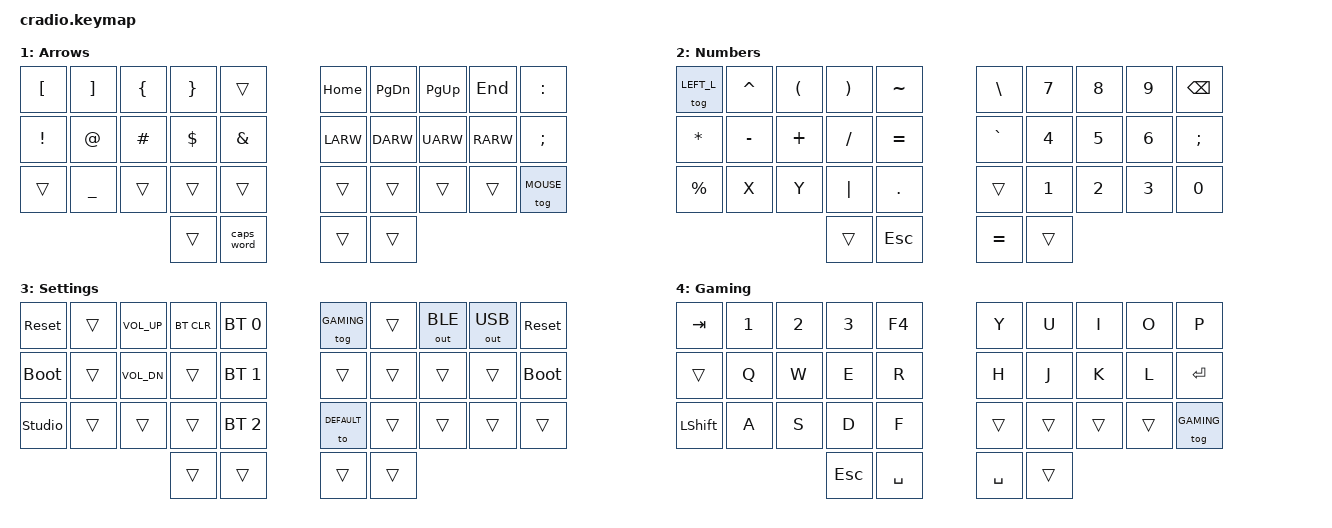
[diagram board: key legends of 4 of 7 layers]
// Copyright (c) 2022 The ZMK Contributors
// SPDX-License-Identifier: MIT

#include <behaviors.dtsi>
#include <dt-bindings/zmk/keys.h>
#include <dt-bindings/zmk/bt.h>
#include <dt-bindings/zmk/outputs.h>

// Homerow mods macro
#define HRML(k1,k2,k3,k4) &ht LSHFT k1 &ht LALT k2  &ht LGUI k3  &ht LCTRL k4
#define HRMR(k1,k2,k3,k4) &ht RCTRL k1  &ht RGUI k2  &ht RALT k3  &ht RSHFT k4
#define HRMLW(k1,k2,k3,k4) &ht LSHFT k1 &ht LALT k2  &ht LCTRL k3  &ht LGUI k4
#define HRMRW(k1,k2,k3,k4) &ht RGUI k1  &ht RCTRL k2  &ht RALT k3  &ht RSHFT k4 
// Layers
#define DEFAULT 0
#define RIGHT_L 1 
#define LEFT_L 2 
#define SETTINGS 3
#define GAMING 4
#define MOUSE 5
#define MEDIA 6 

// Combo Funct
#define COMBO(NAME, BINDINGS, LAYERS, KEYPOS) \
    combo_##NAME { \
        timeout-ms = <50>; \
        bindings = <BINDINGS>; \
        key-positions = <KEYPOS>; \
        layers = <LAYERS>;  \
    };

// Tap Function
/*#define TAP(NAME, keyType, BINDINGS1, keyType2, BINDINGS2, keyType3, BINDINGS3) \
    t_##NAME: tap_##NAME { \
        compatible = "zmk,behavior-tap-dance"; \
        label = "tap##Name"; \
        #binding-cells = <0>; \
        tapping-term-ms = <250>; \
        bindings = <keyType BINDINGS1>, <keyType2 BINDINGS2>, <keyType3 BINDINGS3>; \
    };
*/

/ {
    behaviors {

        ht: hold_tap {
            label = "hold_tap";
            compatible = "zmk,behavior-hold-tap";
            #binding-cells = <2>;
            flavor = "tap-preferred";
            tapping-term-ms = <220>;
            quick-tap-ms = <1>;
            require-prior-idle-ms = <100>;
            bindings = <&kp>, <&kp>;
        };

        numPad: numPad_tap {
            compatible = "zmk,behavior-tap-dance";
            label = "numPad";
            #binding-cells = <0>;
            tapping-term-ms = <250>;
            bindings = <&kp SPACE>, <&tog MOUSE>;
        };

        dt: delete_Tap {
            compatible = "zmk,behavior-tap-dance";
            label = "DELETE_TAP";
            #binding-cells = <0>;
            tapping-term-ms = <200>;
            bindings = <&ht LG(BSPC) BSPC>, <&mo 3>;
        };

        ct: copyTap {
            compatible = "zmk,behavior-tap-dance";
            label = "COPY_TAP";
            #binding-cells = <0>;
            tapping-term-ms = <100>;
            bindings = <&ht LG(V) C>, <&kp LG(X)>;
        };

        Enterspace: EnterTap {
            compatible = "zmk,behavior-tap-dance";
            label = "TAP_DANCE_0";
            #binding-cells = <0>;  
            tapping-term-ms = <200>;
            bindings = <&kp SPACE>, <&kp ENTER>;
        };

        ESCspace: EscTap {
            compatible = "zmk,behavior-tap-dance";
            label = "ESC_TAP";
            #binding-cells = <0>;  
            tapping-term-ms = <250>;
            bindings = <&kp SPACE>, <&kp ESC>;
        };

        BTchange: BT_tap {
            compatible = "zmk,behavior-tap-dance";
            label = "BT_TAP";
            #binding-cells = <0>;
            tapping-term-ms = <200>;
            bindings = <&bt BT_SEL 0>, <&bt BT_CLR>;
        };

        ESCP: ESCP_tap {
            compatible = "zmk,behavior-tap-dance";
            label = "ESCP_tap";
            #binding-cells = <0>;
            tapping-term-ms = <200>;
            bindings = <&kp Y>, <&kp ESC>;
        };
	};
};

/{
   macros {
        theMacro: theMacro {
            label = "THEMACRO";
            compatible = "zmk,behavior-macro";
            #binding-cells = <0>;
            bindings
                = <&kp T &kp H &kp E>;
        };

        gitPush: gitPushMacro {
            label = "GITPUSHMACRO";
            compatible = "zmk,behavior-macro";
            #binding-cells = <0>;
            bindings
                = <&kp G &kp I &kp T &kp SPACE &kp P &kp U &kp S &kp H &kp ENTER>;
        };
        
        gitPull: gitPullMacro {
            label = "GITPULLMACRO";
            compatible = "zmk,behavior-macro";
            #binding-cells = <0>;
            bindings
                = <&kp G &kp I &kp T &kp SPACE &kp P &kp U &kp L &kp L &kp ENTER>;
        };

        gitAdd: gitAddMacro {
            label = "GITADDMACRO";
            compatible = "zmk,behavior-macro";
            #binding-cells = <0>;
            bindings
                = <&kp G &kp I &kp T &kp SPACE &kp A &kp D &kp D &kp SPACE &kp DOT &kp ENTER>;
        };

        gitCommit: gitCommitMacro {
            label = "GITCOMMITMACRO";
            compatible = "zmk,behavior-macro";
            #binding-cells = <0>;
            bindings
                = <&kp G &kp I &kp T &kp SPACE &kp C &kp O &kp M &kp M &kp I &kp T &kp SPACE &kp MINUS &kp M &kp SPACE &kp DQT>;
        };

        clear: clearMacro {
            label = "CLEARMACRO";
            compatible = "zmk,behavior-macro";
            #binding-cells = <0>;
            bindings
                = <&kp C &kp L &kp E &kp A &kp R &kp ENTER>;
        };
    };
};

/{
    conditional_layers {
        compatible = "zmk,conditional-layers";
        tri_layer {
            if-layers = <1 2>;
            then-layer = <SETTINGS>;
        };
    };
};

/{
    combos{
        compatible = "zmk,combos";
        COMBO(easyThe, &theMacro, 1, 3 4)
        COMBO(pushCombo, &gitPush, 1, 14 16)
        COMBO(commitCombo, &gitCommit, 1, 14 15)
        COMBO(pullCombo, &gitPull, 1, 2 14)
        COMBO(addCombo, &gitAdd, 1, 3 14)
        COMBO(clearCombo, &kp LC(L), 1, 31 32)
        COMBO(delete, &kp DEL, 1, 8 9)
    };
};

/{    
    //╭──────────┬──────────┬──────────┬──────────┬──────────╮   ╭──────────┬──────────┬──────────┬──────────┬──────────╮
    //│    0     │    1     │    2     │     3    │   4      │   │     5    │   6      │     7    │     8    │    9     │
    //├──────────┼──────────┼──────────┼──────────┼──────────┤   ├──────────┼──────────┼──────────┼──────────┼──────────┤
    //│    10    │    11    │    12    │   13     │   14     │   │   15     │    16    │    17    │    18    │    19    │
    //├──────────┼──────────┼──────────┼──────────┼──────────┤   ├──────────┼──────────┼──────────┼──────────┼──────────┤
    //│     20   │    21    │   22     │   23     │     24   │   │    25    │    26    │   27     │    28    │   29     │
    //╰──────────┴──────────┴──────────┼──────────┼──────────┤   ├──────────┼──────────┼──────────┴──────────┴──────────╯
    //                                 |    30    |     31   |   |    32    |    33    |
    //                                 ╰──────────┴──────────╯   ╰──────────┴──────────╯

    keymap {
        compatible = "zmk,keymap";
        default_layer {
            display-name = "Main";
            bindings = <    
        //╭──────────┬──────────┬──────────┬──────────┬──────────╮   ╭──────────┬──────────┬──────────┬──────────┬──────────╮
        //│  Q       │  W       │  E       │  R       │  T       │   │  Y       │  U       │  I       │  O       │  P       │
            &kp Q      &kp W      &kp E      &kp R      &kp T          &ESCP      &kp U      &kp I      &kp O      &kp P
        //├──────────┼──────────┼──────────┼──────────┼──────────┤   ├──────────┼──────────┼──────────┼──────────┼──────────┤
        //│  A       │  S       │  D       │  F       │  G       │   │  H       │  J       │  K       │  L       │ ' "      │
            HRML(A,     S,         D,         F)     &kp G           &kp H      HRMR(J,        K,         L,       SQT)
        //├──────────┼──────────┼──────────┼──────────┼──────────┤   ├──────────┼──────────┼──────────┼──────────┼──────────┤
        //│  Z       │  X       │  C       │  V       │  B       │   │  N       │  M       │ , <      │ . >      │ / ?      │
            &kp Z      &kp X      &kp C      &kp V      &kp B          &kp N      &kp M      &kp COMMA  &kp DOT    &kp FSLH
        //╰──────────┴──────────┴──────────┼──────────┼──────────┤   ├──────────┼──────────┼──────────┴──────────┴──────────╯
                                        &lt LEFT_L TAB &ESCspace        &Enterspace &lt RIGHT_L BSPC
        //                                 ╰──────────┴──────────╯   ╰──────────┴──────────╯
            >;
        };

        right_layer {
            display-name = "Arrows";
            bindings = <
        //╭──────────┬──────────┬──────────┬──────────┬──────────╮   ╭──────────┬──────────┬──────────┬──────────┬──────────╮
        //│ [        │  ]       │  {       │  }       │          │   │ HOME     │ PAGE DN  │ PAGE UP  │ END      │  :       │
           &kp LBKT  &kp RBKT   &kp LBRC    &kp RBRC   &trans          &kp HOME   &kp PG_DN  &kp PG_UP  &kp END    &kp COLON
        //├──────────┼──────────┼──────────┼──────────┼──────────┤   ├──────────┼──────────┼──────────┼──────────┼──────────┤
        //│     !    │  @       │    #     │      $   │     &    │   │ LEFT     │ DOWN     │ UP       │ RIGHT    │  ;       │
            &kp EXCL    &kp AT   &kp HASH   &kp DLLR   &kp AMPS       &kp LARW   &kp DARW   &kp UARW   &kp RARW   &kp SEMI
        //├──────────┼──────────┼──────────┼──────────┼──────────┤   ├──────────┼──────────┼──────────┼──────────┼──────────┤
        //│          │   _      │          │          │          │   │          │          │          │          │          │
           &trans     &kp UNDER     &trans      &trans      &trans       &trans     &trans     &trans     &trans  &tog MOUSE
        //╰──────────┴──────────┴──────────┼──────────┼──────────┤   ├──────────┼──────────┼──────────┴──────────┴──────────╯
                                            &trans    &caps_word        &trans     &trans
        //                                 ╰──────────┴──────────╯   ╰──────────┴──────────╯
            >;
        };

        left_layer {
            display-name = "Numbers";
            bindings = <
        //╭──────────┬──────────┬──────────┬──────────┬──────────╮   ╭──────────┬──────────┬──────────┬──────────┬──────────╮
        //│ Tog        │  ^       │  (       │  )       │    ~     │   │     \    │     7    │    8     │     9    │          │
            &tog LEFT_L  &kp CARET   &kp LPAR   &kp RPAR   &kp TILDE     &kp BSLH     &kp N7     &kp N8       &kp N9    &kp BSPC
        //├──────────┼──────────┼──────────┼──────────┼──────────┤   ├──────────┼──────────┼──────────┼──────────┼──────────┤
        //│    *     │    -     │     +    │     /    │     =    │   │     `    │    4     │   5      │    6     │  ;       │
            &kp ASTRK  &kp MINUS  &kp PLUS  &kp FSLH   &kp EQUAL      &kp GRAVE     &kp N4    &kp N5     &kp N6     &kp SEMI
        //├──────────┼──────────┼──────────┼──────────┼──────────┤   ├──────────┼──────────┼──────────┼──────────┼──────────┤
        //│  %       │   X      │    Y     │     │    │    .     │   │          │    1     │    2     │     3    │     =    │
           &kp PRCNT   &kp X      &kp Y      &kp PIPE   &kp DOT         &trans     &kp N1     &kp N2     &kp N3     &kp N0
        //╰──────────┴──────────┴──────────┼──────────┼──────────┤   ├──────────┼──────────┼──────────┴──────────┴──────────╯
                                             &trans     &kp ESC        &kp EQUAL &trans
        //                                 ╰──────────┴──────────╯   ╰──────────┴──────────╯
            >;
        };

        tri_layer {
            display-name = "Settings";
            bindings = <
        //╭──────────┬──────────┬──────────┬──────────┬──────────╮   ╭──────────┬──────────┬──────────┬──────────┬──────────╮
        //│ RESET    │          │          │ Clear BT │PROFILE 0 │   │          │          |Bluetooth |  Dongle  │  RESET   │
        &sys_reset  &trans  &kp C_VOL_UP    &bt BT_CLR  &bt BT_SEL 0 &tog GAMING  &trans   &out OUT_BLE &out OUT_USB    &sys_reset
        //├──────────┼──────────┼──────────┼──────────┼──────────┤   ├──────────┼──────────┼──────────┼──────────┼──────────┤
        //│BOOTLOADER│          │          │          │PROFILE 1 │   │          │          │          │          │BOOTLOADER│
          &bootloader  &trans  &kp C_VOL_DN     &trans    &bt BT_SEL 1   &trans     &trans     &trans     &trans    &bootloader
        //├──────────┼──────────┼──────────┼──────────┼──────────┤   ├──────────┼──────────┼──────────┼──────────┼──────────┤
        //│          │          │          │          │PROFILE 2 │   │          │          │          │          │          │
          &studio_unlock   &trans &trans    &trans    &bt BT_SEL 2    &to DEFAULT     &trans     &trans     &trans     &trans
        //╰──────────┴──────────┴──────────┼──────────┼──────────┤   ├──────────┼──────────┼──────────┴──────────┴──────────╯
                                             &trans     &trans         &trans     &trans
        //                                 ╰──────────┴──────────╯   ╰──────────┴──────────╯
            >;
        };

        gaming_layer {
            display-name = "Gaming";
            bindings = <
        //╭──────────┬──────────┬──────────┬──────────┬──────────╮   ╭──────────┬──────────┬──────────┬──────────┬──────────╮
        //│          │     1    │     2    │    3     │   F4     │   │ Y        │    U     │    I     │   O      │     P    │
            &kp TAB    &kp N1      &kp N2      &kp N3   &kp F4         &kp Y      &kp U      &kp I      &kp O     &kp P
        //├──────────┼──────────┼──────────┼──────────┼──────────┤   ├──────────┼──────────┼──────────┼──────────┼──────────┤
        //│          │     Q    │    W     │    E     │   R      │   │ H        │ J        │ K        │ L        │  Enter   │
            &trans     &kp Q     &kp W     &kp E        &kp R         &kp H      &kp J      &kp K       &kp L     &kp ENTER
        //├──────────┼──────────┼──────────┼──────────┼──────────┤   ├──────────┼──────────┼──────────┼──────────┼──────────┤
        //│ LSHIFT   │    A     │    S     │    D     │   F      │   │          │          │          │          │          │
            &kp LSHIFT    &kp A    &kp S     &kp D     &kp F         &trans     &trans     &trans     &trans     &tog GAMING
        //╰──────────┴──────────┴──────────┼──────────┼──────────┤   ├──────────┼──────────┼──────────┴──────────┴──────────╯
                                             &kp ESC     &kp SPACE     &kp SPACE  &trans
        //                                 ╰──────────┴──────────╯   ╰──────────┴──────────╯
            >;
        };

        // Potential Git/ coding layer??
        // Git add, commit, push
        // terminal stuff? ie. clear and stuff

        num_layer  {
            bindings = <
        //╭──────────┬──────────┬──────────┬──────────┬──────────╮   ╭──────────┬──────────┬──────────┬──────────┬──────────╮
        //│          │          │          │          │          │   │     7    │   8      │ 9        │          │          │
            &none    &none      &none      &none     &none                &kp 8     &kp 9      &none      &none
        //├──────────┼──────────┼──────────┼──────────┼──────────┤   ├──────────┼──────────┼──────────┼──────────┼──────────┤
        //│          │          │          │          │          │   │    4     │ 5        │ 6        │          │          │
            &none     &none     &none       &none      &gitPush          &none       &kp 5       &kp 6      &none     &none
        //├──────────┼──────────┼──────────┼──────────┼──────────┤   ├──────────┼──────────┼──────────┼──────────┼──────────┤
        //│          │          │          │          │          │   │    1     │    2     │   3      │          │          │
            &none     &none      &none       &none     &none          &kp 1      &kp 2      &kp 3      &trans      &trans
        //╰──────────┴──────────┴──────────┼──────────┼──────────┤   ├──────────┼──────────┼──────────┴──────────┴──────────╯
                                           &tog MOUSE  &none          &none       &none
        //                                 ╰──────────┴──────────╯   ╰──────────┴──────────╯
            >;
        };
        media_layer {
            bindings = <
        //╭──────────┬──────────┬──────────┬──────────┬──────────╮   ╭──────────┬──────────┬──────────┬──────────┬──────────╮
        //│          │          │          │          │          │   │     7    │   8      │ 9        │          │          │
          &kp C_VOL_UP    &none      &none      &none     &none       &kp 8     &kp 9      &none      &none
        //├──────────┼──────────┼──────────┼──────────┼──────────┤   ├──────────┼──────────┼──────────┼──────────┼──────────┤
        //│          │          │          │          │          │   │    4     │ 5        │ 6        │          │          │
          &kp C_VOL_DN     &none     &none       &none      &gitPush          &none       &kp 5       &kp 6      &none     &none
        //├──────────┼──────────┼──────────┼──────────┼──────────┤   ├──────────┼──────────┼──────────┼──────────┼──────────┤
        //│          │          │          │          │          │   │    1     │    2     │   3      │          │          │
            &none     &none      &none       &none     &none          &kp 1      &kp 2      &kp 3      &trans      &trans
        //╰──────────┴──────────┴──────────┼──────────┼──────────┤   ├──────────┼──────────┼──────────┴──────────┴──────────╯
                                             &trans     &none         &none      &none
        //                                 ╰──────────┴──────────╯   ╰──────────┴──────────╯
            >;
        };
 
    };
};
